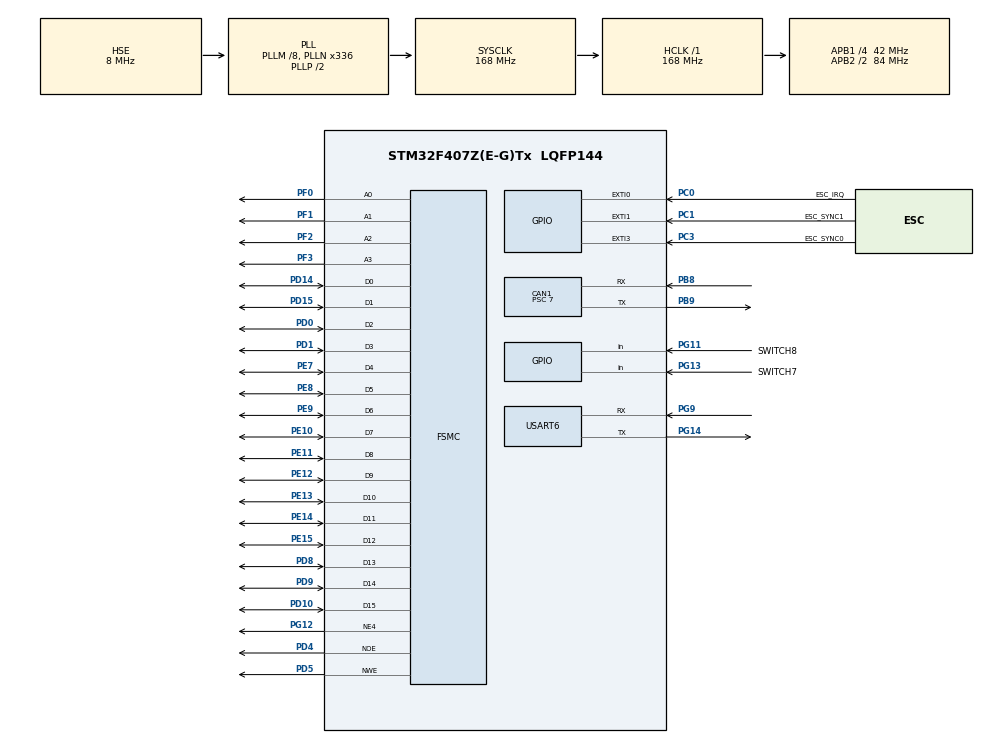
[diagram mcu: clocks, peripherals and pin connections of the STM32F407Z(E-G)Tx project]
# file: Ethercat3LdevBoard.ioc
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CAN1.BS1=CAN_BS1_5TQ
CAN1.BS2=CAN_BS2_6TQ
CAN1.CalculateTimeQuantum=166.66666666666669
CAN1.Prescaler=7
FSMC.DataSetupTime1=15
FSMC.WriteOperation1=FSMC_WRITE_OPERATION_ENABLE
Mcu.Family=STM32F4
Mcu.Name=STM32F407Z(E-G)Tx
Mcu.Package=LQFP144
NVIC.CAN1_RX0_IRQn=true\:0\:0\:false\:false\:true\:true\:true
NVIC.EXTI0_IRQn=true\:1\:0\:true\:false\:true\:true\:true
NVIC.EXTI1_IRQn=true\:1\:0\:true\:false\:true\:true\:true
NVIC.EXTI3_IRQn=true\:1\:0\:true\:false\:true\:true\:true
NVIC.PriorityGroup=NVIC_PRIORITYGROUP_2
NVIC.TIM2_IRQn=true\:0\:0\:false\:false\:true\:true\:true
NVIC.USART6_IRQn=true\:0\:0\:false\:false\:true\:true\:true
PB7.Signal=FSMC_NL
PB8.Mode=Master
PB8.Signal=CAN1_RX
PB9.Mode=Master
PB9.Signal=CAN1_TX
PC0.GPIO_Label=ESC_IRQ
PC0.GPIO_ModeDefaultEXTI=GPIO_MODE_IT_FALLING
PC0.Signal=GPXTI0
PC1.GPIO_Label=ESC_SYNC1
PC1.GPIO_ModeDefaultEXTI=GPIO_MODE_IT_FALLING
PC1.Signal=GPXTI1
PC3.GPIO_Label=ESC_SYNC0
PC3.GPIO_ModeDefaultEXTI=GPIO_MODE_IT_FALLING
PC3.Signal=GPXTI3
PD0.Signal=FSMC_D2_DA2
PD1.Signal=FSMC_D3_DA3
PD10.Signal=FSMC_D15_DA15
PD14.Signal=FSMC_D0_DA0
PD15.Signal=FSMC_D1_DA1
PD4.Signal=FSMC_NOE
PD5.Signal=FSMC_NWE
PD8.Signal=FSMC_D13_DA13
PD9.Signal=FSMC_D14_DA14
PE10.Signal=FSMC_D7_DA7
PE11.Signal=FSMC_D8_DA8
PE12.Signal=FSMC_D9_DA9
PE13.Signal=FSMC_D10_DA10
PE14.Signal=FSMC_D11_DA11
PE15.Signal=FSMC_D12_DA12
PE7.Signal=FSMC_D4_DA4
PE8.Signal=FSMC_D5_DA5
PE9.Signal=FSMC_D6_DA6
PF0.Signal=FSMC_A0
PF1.Signal=FSMC_A1
PF2.Signal=FSMC_A2
PF3.Signal=FSMC_A3
PG11.GPIO_Label=SWITCH8
PG11.Signal=GPIO_Input
PG12.Mode=NorPsramChipSelect4_1
PG12.Signal=FSMC_NE4
PG13.GPIO_Label=SWITCH7
PG13.Signal=GPIO_Input
PG14.Mode=Asynchronous
PG14.Signal=USART6_TX
PG9.Mode=Asynchronous
PG9.Signal=USART6_RX
PH0-OSC_IN.Mode=HSE-External-Oscillator
PH0-OSC_IN.Signal=RCC_OSC_IN
PH1-OSC_OUT.Mode=HSE-External-Oscillator
PH1-OSC_OUT.Signal=RCC_OSC_OUT
ProjectManager.HeapSize=0x200
ProjectManager.StackSize=0x400
ProjectManager.TargetToolchain=MDK-ARM V5.27
RCC.48MHZClocksFreq_Value=84000000
RCC.AHBFreq_Value=168000000
RCC.APB1CLKDivider=RCC_HCLK_DIV4
RCC.APB1Freq_Value=42000000
RCC.APB1TimFreq_Value=84000000
RCC.APB2CLKDivider=RCC_HCLK_DIV2
RCC.APB2Freq_Value=84000000
RCC.APB2TimFreq_Value=168000000
RCC.CortexFreq_Value=168000000
RCC.HCLKFreq_Value=168000000
RCC.HSE_VALUE=8000000
RCC.HSI_VALUE=16000000
RCC.LSE_VALUE=32768
RCC.PLLM=8
RCC.PLLN=336
RCC.PLLSourceVirtual=RCC_PLLSOURCE_HSE
RCC.SYSCLKFreq_VALUE=168000000
RCC.SYSCLKSource=RCC_SYSCLKSOURCE_PLLCLK
RCC.VCOOutputFreq_Value=336000000
SH.FSMC_A0.0=FSMC_A0,4b-a1
SH.FSMC_A1.0=FSMC_A1,4b-a1
SH.FSMC_A2.0=FSMC_A2,4b-a1
SH.FSMC_A3.0=FSMC_A3,4b-a1
SH.FSMC_D0_DA0.0=FSMC_D0,16b-d1
SH.FSMC_D10_DA10.0=FSMC_D10,16b-d1
SH.FSMC_D11_DA11.0=FSMC_D11,16b-d1
SH.FSMC_D12_DA12.0=FSMC_D12,16b-d1
SH.FSMC_D13_DA13.0=FSMC_D13,16b-d1
SH.FSMC_D14_DA14.0=FSMC_D14,16b-d1
SH.FSMC_D15_DA15.0=FSMC_D15,16b-d1
SH.FSMC_D1_DA1.0=FSMC_D1,16b-d1
SH.FSMC_D2_DA2.0=FSMC_D2,16b-d1
SH.FSMC_D3_DA3.0=FSMC_D3,16b-d1
SH.FSMC_D4_DA4.0=FSMC_D4,16b-d1
SH.FSMC_D5_DA5.0=FSMC_D5,16b-d1
SH.FSMC_D6_DA6.0=FSMC_D6,16b-d1
SH.FSMC_D7_DA7.0=FSMC_D7,16b-d1
SH.FSMC_D8_DA8.0=FSMC_D8,16b-d1
SH.FSMC_D9_DA9.0=FSMC_D9,16b-d1
SH.FSMC_NL.0=FSMC_NL
SH.FSMC_NOE.0=FSMC_NOE,NorFlash1
SH.FSMC_NWE.0=FSMC_NWE,NorFlash1
TIM2.Period=2000
TIM2.Prescaler=41
USART6.VirtualMode=VM_ASYNC
VP_TIM2_VS_ClockSourceINT.Mode=Internal
board=custom

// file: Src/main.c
/* USER CODE BEGIN Header */
/**
  ******************************************************************************
  * @file           : main.c
  * @brief          : Main program body
  ******************************************************************************
  * @attention
  *
  * <h2><center>&copy; Copyright (c) 2020 STMicroelectronics.
  * All rights reserved.</center></h2>
  *
  * This software component is licensed by ST under BSD 3-Clause license,
  * the "License"; You may not use this file except in compliance with the
  * License. You may obtain a copy of the License at:
  *                        opensource.org/licenses/BSD-3-Clause
  *
  ******************************************************************************
  */
/* USER CODE END Header */

#include "main.h"

/* USER CODE BEGIN Includes */
#include "applInterface.h"
#include "esc_can.h"
#include "esc_timer.h"
#include "esc_fsmc.h"
#include "esc_uart.h"
#include "user_app.h"
/* USER CODE END Includes */

void SystemClock_Config(void);
static void MX_GPIO_Init(void);

/* USER CODE BEGIN 0 */
extern CAN_HandleTypeDef hcan1;
extern uint8_t CAN_Rx_Flag;
uint8_t tx_buf[]="dan uest";
uint8_t result;
/* USER CODE END 0 */

int main(void)
{

  /* MCU Configuration--------------------------------------------------------*/

  /* Reset of all peripherals, Initializes the Flash interface and the Systick. */
  HAL_Init();

  /* Configure the system clock */
  SystemClock_Config();

  /* Initialize all configured peripherals */
  MX_GPIO_Init();
  MX_CAN1_Init();
  MX_FSMC_Init();
  MX_TIM2_Init();
  MX_USART6_UART_Init();
  /* USER CODE BEGIN 2 */

  CAN_User_Init(&hcan1);

//  HW_Init();
//  MainInit();

  /* USER CODE END 2 */

  /* Infinite loop */
  while (1)
  {

    /* USER CODE BEGIN 3 */

//	  MainLoop();
//	  Process();

	  if(CAN_Rx_Flag){
		CANx_SendNormalData(&hcan1,0xAA,tx_buf,8);
		  CAN_Rx_Flag = 0;
	  }
  }
  /* USER CODE END 3 */
}

void SystemClock_Config(void)
{
  RCC_OscInitTypeDef RCC_OscInitStruct = {0};
  RCC_ClkInitTypeDef RCC_ClkInitStruct = {0};

  /** Configure the main internal regulator output voltage
  */
  __HAL_RCC_PWR_CLK_ENABLE();
  __HAL_PWR_VOLTAGESCALING_CONFIG(PWR_REGULATOR_VOLTAGE_SCALE1);
  /** Initializes the CPU, AHB and APB busses clocks
  */
  RCC_OscInitStruct.OscillatorType = RCC_OSCILLATORTYPE_HSE;
  RCC_OscInitStruct.HSEState = RCC_HSE_ON;
  RCC_OscInitStruct.PLL.PLLState = RCC_PLL_ON;
  RCC_OscInitStruct.PLL.PLLSource = RCC_PLLSOURCE_HSE;
  RCC_OscInitStruct.PLL.PLLM = 8;
  RCC_OscInitStruct.PLL.PLLN = 336;
  RCC_OscInitStruct.PLL.PLLP = RCC_PLLP_DIV2;
  RCC_OscInitStruct.PLL.PLLQ = 4;
  if (HAL_RCC_OscConfig(&RCC_OscInitStruct) != HAL_OK)
  {
    Error_Handler();
  }
  /** Initializes the CPU, AHB and APB busses clocks
  */
  RCC_ClkInitStruct.ClockType = RCC_CLOCKTYPE_HCLK|RCC_CLOCKTYPE_SYSCLK
                              |RCC_CLOCKTYPE_PCLK1|RCC_CLOCKTYPE_PCLK2;
  RCC_ClkInitStruct.SYSCLKSource = RCC_SYSCLKSOURCE_PLLCLK;
  RCC_ClkInitStruct.AHBCLKDivider = RCC_SYSCLK_DIV1;
  RCC_ClkInitStruct.APB1CLKDivider = RCC_HCLK_DIV4;
  RCC_ClkInitStruct.APB2CLKDivider = RCC_HCLK_DIV2;

  if (HAL_RCC_ClockConfig(&RCC_ClkInitStruct, FLASH_LATENCY_5) != HAL_OK)
  {
    Error_Handler();
  }
}

static void MX_GPIO_Init(void)
{
  GPIO_InitTypeDef GPIO_InitStruct = {0};

  /* GPIO Ports Clock Enable */
  __HAL_RCC_GPIOF_CLK_ENABLE();
  __HAL_RCC_GPIOH_CLK_ENABLE();
  __HAL_RCC_GPIOC_CLK_ENABLE();
  __HAL_RCC_GPIOE_CLK_ENABLE();
  __HAL_RCC_GPIOD_CLK_ENABLE();
  __HAL_RCC_GPIOG_CLK_ENABLE();
  __HAL_RCC_GPIOB_CLK_ENABLE();

  /*Configure GPIO pins : ESC_IRQ_Pin ESC_SYNC1_Pin ESC_SYNC0_Pin */
  GPIO_InitStruct.Pin = ESC_IRQ_Pin|ESC_SYNC1_Pin|ESC_SYNC0_Pin;
  GPIO_InitStruct.Mode = GPIO_MODE_IT_FALLING;
  GPIO_InitStruct.Pull = GPIO_NOPULL;
  HAL_GPIO_Init(GPIOC, &GPIO_InitStruct);

  /*Configure GPIO pins : SWITCH8_Pin SWITCH7_Pin */
  GPIO_InitStruct.Pin = SWITCH8_Pin|SWITCH7_Pin;
  GPIO_InitStruct.Mode = GPIO_MODE_INPUT;
  GPIO_InitStruct.Pull = GPIO_NOPULL;
  HAL_GPIO_Init(GPIOG, &GPIO_InitStruct);

  /* EXTI interrupt init*/
  HAL_NVIC_SetPriority(EXTI0_IRQn, 1, 0);
  HAL_NVIC_EnableIRQ(EXTI0_IRQn);

  HAL_NVIC_SetPriority(EXTI1_IRQn, 1, 0);
  HAL_NVIC_EnableIRQ(EXTI1_IRQn);

  HAL_NVIC_SetPriority(EXTI3_IRQn, 1, 0);
  HAL_NVIC_EnableIRQ(EXTI3_IRQn);

}

void Error_Handler(void)
{
}

/************************ (C) COPYRIGHT STMicroelectronics *****END OF FILE****/
